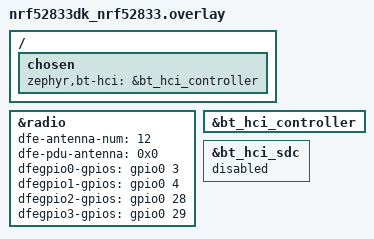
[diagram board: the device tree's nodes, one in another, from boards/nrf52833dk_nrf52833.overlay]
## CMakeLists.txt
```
#
# Copyright (c) 2021 Nordic Semiconductor ASA
#
# SPDX-License-Identifier: LicenseRef-Nordic-5-Clause

cmake_minimum_required(VERSION 3.20.0)

find_package(Zephyr REQUIRED HINTS $ENV{ZEPHYR_BASE})

project(direction_finding_connectionless)

# NORDIC SDK APP START
target_sources(app PRIVATE
  src/main.c
)
# NORDIC SDK APP END
```

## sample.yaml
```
sample:
  name: Direction Finding Connectionless Beacon
  description: Sample application showing connectionless Direction Finding transmission
common:
  tags:
    - bluetooth
    - sysbuild
    - ci_samples_bluetooth
tests:
  sample.bluetooth.direction_finding_connectionless_tx.aoa.sdc:
    sysbuild: true
    platform_allow:
      - nrf5340dk/nrf5340/cpuapp
      - nrf54l15dk/nrf54l05/cpuapp
      - nrf54l15dk/nrf54l10/cpuapp
      - nrf54l15dk/nrf54l15/cpuapp
      - nrf54lm20dk/nrf54lm20a/cpuapp
      - nrf54lm20dk/nrf54lm20b/cpuapp
      - nrf54lv10dk/nrf54lv10a/cpuapp
      - nrf54lv10dk/nrf54lv10a/cpuapp/ns
      - nrf54lc10dk/nrf54lc10a/cpuapp
      - nrf54lc10dk/nrf54lc10a/cpuapp/ns
    integration_platforms:
      - nrf5340dk/nrf5340/cpuapp
      - nrf54l15dk/nrf54l15/cpuapp
    harness: console
    harness_config:
      type: multi_line
      ordered: true
      regex:
        - "Starting Connectionless Beacon Demo"
        - "Bluetooth initialization...success"
        - "Periodic advertising enable...success"
        - "Extended advertising enable...success"
    timeout: 15
  sample.bluetooth.direction_finding_connectionless_tx.aoa.bt_ll_sw_split.nrf53:
    sysbuild: true
    build_only: true
    extra_args:
      - ipc_radio_OVERLAY_CONFIG="../../overlay-bt_ll_sw_split.conf"
      - ipc_radio_SNIPPET="bt-ll-sw-split"
    platform_allow:
      - nrf5340dk/nrf5340/cpuapp
    integration_platforms:
      - nrf5340dk/nrf5340/cpuapp
  sample.bluetooth.direction_finding_connectionless_tx.aod.bt_ll_sw_split.nrf53:
    sysbuild: true
    build_only: true
    extra_args:
      - OVERLAY_CONFIG="overlay-aod.conf"
      - ipc_radio_OVERLAY_CONFIG="../../overlay-bt_ll_sw_split.conf"
      - ipc_radio_SNIPPET="bt-ll-sw-split"
    platform_allow:
      - nrf5340dk/nrf5340/cpuapp
    integration_platforms:
      - nrf5340dk/nrf5340/cpuapp
```

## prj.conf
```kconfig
#
# Copyright (c) 2021 Nordic Semiconductor ASA
#
# SPDX-License-Identifier: LicenseRef-Nordic-5-Clause
#

CONFIG_BT=y
CONFIG_BT_DEVICE_NAME="DF Connectionless Beacon App"

CONFIG_BT_EXT_ADV=y
CONFIG_BT_PER_ADV=y
CONFIG_BT_BROADCASTER=y

# Enable Direction Finding Feature
CONFIG_BT_DF=y
CONFIG_BT_DF_CONNECTIONLESS_CTE_TX=y

# Disable AoD Feature (antenna switching) in Tx mode in Host
CONFIG_BT_DF_CTE_TX_AOD=n

# Enable old clock_control_nrf api implementation for mpsl to use
CONFIG_CLOCK_CONTROL_NRF=y
```

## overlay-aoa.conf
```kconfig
#
# Copyright (c) 2021 Nordic Semiconductor ASA
#
# SPDX-License-Identifier: LicenseRef-Nordic-5-Clause
#

# Disable AoD Feature (antenna switching) in Tx mode in Controller and Host
CONFIG_BT_CTLR_DF_ANT_SWITCH_TX=n
CONFIG_BT_DF_CTE_TX_AOD=n
```

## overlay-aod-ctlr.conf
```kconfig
#
# Copyright (c) 2021 Nordic Semiconductor ASA
#
# SPDX-License-Identifier: LicenseRef-Nordic-5-Clause
#

# Controller part of the AoD configuration. It belongs to the image that holds
# the Bluetooth controller: the application image on single-core boards, and the
# ipc_radio image on boards with a dedicated radio core (nRF53). In an image
# without the controller, HAS_BT_CTLR is not set and this line has no effect.
CONFIG_BT_CTLR_DF_ANT_SWITCH_TX=y
```

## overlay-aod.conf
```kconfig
#
# Copyright (c) 2021 Nordic Semiconductor ASA
#
# SPDX-License-Identifier: LicenseRef-Nordic-5-Clause
#

# Enable AoD Feature (antenna switching) in Tx mode in the Host
# Ineffective here: unsatisfied dependencies BT_CTLR_DF_CTE_TX, BT_CTLR_DF, HAS_BT_CTLR, so
# BT_CTLR_DF_ANT_SWITCH_TX stays n whenever this overlay is applied to an image without the
# controller; moved to overlay-aod-ctlr.conf, which is applied to the image that holds it.
# CONFIG_BT_CTLR_DF_ANT_SWITCH_TX=y
CONFIG_BT_DF_CTE_TX_AOD=y
```

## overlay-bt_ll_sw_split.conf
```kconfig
#
# Copyright (c) 2021 Nordic Semiconductor ASA
#
# SPDX-License-Identifier: LicenseRef-Nordic-5-Clause
#

CONFIG_BT_CTLR_ADV_EXT=y
CONFIG_BT_CTLR_ADV_PERIODIC=y

# Enable Direction Finding TX Feature
CONFIG_BT_CTLR_DF=y

# Disable Direction Finding RX mode
CONFIG_BT_CTLR_DF_ANT_SWITCH_RX=n
CONFIG_BT_CTLR_DF_SCAN_CTE_RX=n

# Enable chaining of multiple CTEs in periodic advertising
CONFIG_BT_CTLR_ADVANCED_FEATURES=y
CONFIG_BT_CTLR_ADV_SYNC_PDU_BACK2BACK=y
CONFIG_BT_CTLR_DF_PER_ADV_CTE_NUM_MAX=16
```

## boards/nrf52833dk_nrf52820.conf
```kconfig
#
# Copyright (c) 2021 Nordic Semiconductor ASA
#
# SPDX-License-Identifier: LicenseRef-Nordic-5-Clause
#

# Enable Direction Finding TX Feature
CONFIG_BT_CTLR_DF=y

# Disable Direction Finding RX mode
CONFIG_BT_CTLR_DF_ANT_SWITCH_RX=n
CONFIG_BT_CTLR_DF_SCAN_CTE_RX=n

# Disable AoD Feature (antenna switching) in Tx mode in Controller
CONFIG_BT_CTLR_DF_ANT_SWITCH_TX=n
```

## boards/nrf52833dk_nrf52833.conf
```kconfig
#
# Copyright (c) 2021 Nordic Semiconductor ASA
#
# SPDX-License-Identifier: LicenseRef-Nordic-5-Clause
#
# Enable Direction Finding Feature
CONFIG_BT_CTLR_DF=y

# Disable Direction Finding RX mode
CONFIG_BT_CTLR_DF_SCAN_CTE_RX=n
CONFIG_BT_CTLR_DF_ANT_SWITCH_RX=n

# Disable AoD Feature (antenna switching) in Tx mode in Controller
CONFIG_BT_CTLR_DF_ANT_SWITCH_TX=n
```

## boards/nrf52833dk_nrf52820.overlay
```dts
/*
 * Copyright (c) 2021 Nordic Semiconductor ASA
 *
 * SPDX-License-Identifier: LicenseRef-Nordic-5-Clause
 */

&radio {
	status = "okay";
	/* This is a number of antennas that are available on antenna matrix
	 * designed by Nordic. For more information see README.rst.
	 */
	dfe-antenna-num = <12>;
	/* This is a setting that enables antenna 12 (in antenna matrix designed
	 * by Nordic) for Tx PDU. For more information see README.rst.
	 */
	dfe-pdu-antenna = <0x0>;

	/* These are GPIO pin numbers that are provided to
	 * Radio peripheral. The pins will be acquired by Radio to
	 * drive antenna switching when AoD is enabled.
	 * Pin numbers are selected to drive switches on antenna matrix
	 * desinged by Nordic. For more information see README.rst.
	 */
	dfegpio0-gpios = <&gpio0 3 0>;
	dfegpio1-gpios = <&gpio0 4 0>;
	dfegpio2-gpios = <&gpio0 28 0>;
	dfegpio3-gpios = <&gpio0 29 0>;
};
```

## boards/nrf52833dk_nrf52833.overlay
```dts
/*
 * Copyright (c) 2021 Nordic Semiconductor ASA
 *
 * SPDX-License-Identifier: LicenseRef-Nordic-5-Clause
 */

&radio {
	status = "okay";
	/* This is a number of antennas that are available on antenna matrix
	 * designed by Nordic. For more information see README.rst.
	 */
	dfe-antenna-num = <12>;
	/* This is a setting that enables antenna 12 (in antenna matrix designed
	 * by Nordic) for Tx PDU. For more information see README.rst.
	 */
	dfe-pdu-antenna = <0x0>;

	/* These are GPIO pin numbers that are provided to
	 * Radio peripheral. The pins will be acquired by Radio to
	 * drive antenna switching when AoD is enabled.
	 * Pin numbers are selected to drive switches on antenna matrix
	 * desinged by Nordic. For more information see README.rst.
	 */
	dfegpio0-gpios = <&gpio0 3 0>;
	dfegpio1-gpios = <&gpio0 4 0>;
	dfegpio2-gpios = <&gpio0 28 0>;
	dfegpio3-gpios = <&gpio0 29 0>;
};

&bt_hci_controller {
	status = "okay";
};

&bt_hci_sdc {
	status = "disabled";
};

/ {
	chosen {
		zephyr,bt-hci = &bt_hci_controller;
	};
};
```

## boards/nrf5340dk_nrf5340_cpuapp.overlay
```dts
/*
 * Copyright (c) 2022 Nordic Semiconductor ASA
 *
 * SPDX-License-Identifier: LicenseRef-Nordic-5-Clause
 */

/* Enable pin forwarding to the network core. The selected pins will be used by
 * the Radio Direction Finding Extension for antenna switching purposes.
 *
 * Note: Pay attention to assigning the same GPIO pins as those provided in
 * the network core DTS overlay.
 */
&gpio_fwd {
	dfe-gpio-if {
		gpios = <&gpio0 4 0>,
			<&gpio0 5 0>,
			<&gpio0 6 0>,
			<&gpio0 7 0>;
		};
};
```

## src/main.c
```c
/*
 * Copyright (c) 2021 Nordic Semiconductor ASA
 *
 * SPDX-License-Identifier: LicenseRef-Nordic-5-Clause
 */

#include <zephyr/types.h>
#include <stddef.h>
#include <errno.h>
#include <zephyr/kernel.h>
#include <zephyr/sys/printk.h>

#include <zephyr/bluetooth/bluetooth.h>
#include <zephyr/bluetooth/direction.h>
#include <zephyr/sys/byteorder.h>
#include <zephyr/sys/util.h>

/* Length of CTE in unit of 8[us] */
#define CTE_LEN (0x14U)
/* Number of CTE send in single periodic advertising train */
#define PER_ADV_EVENT_CTE_COUNT 5

static const struct bt_data ad[] = {
	BT_DATA(BT_DATA_NAME_COMPLETE, CONFIG_BT_DEVICE_NAME, sizeof(CONFIG_BT_DEVICE_NAME) - 1),
};

static void adv_sent_cb(struct bt_le_ext_adv *adv,
			struct bt_le_ext_adv_sent_info *info);

const static struct bt_le_ext_adv_cb adv_callbacks = {
	.sent = adv_sent_cb,
};

static struct bt_le_ext_adv *adv_set;

const static struct bt_le_adv_param param =
		BT_LE_ADV_PARAM_INIT(BT_LE_ADV_OPT_EXT_ADV,
				     BT_GAP_ADV_FAST_INT_MIN_2,
				     BT_GAP_ADV_FAST_INT_MAX_2,
				     NULL);

static struct bt_le_ext_adv_start_param ext_adv_start_param = {
	.timeout = 0,
	.num_events = 0,
};

const static struct bt_le_per_adv_param per_adv_param = {
	.interval_min = BT_GAP_PER_ADV_SLOW_INT_MIN,
	.interval_max = BT_GAP_PER_ADV_SLOW_INT_MAX,
	.options = BT_LE_ADV_OPT_USE_TX_POWER,
};

#if defined(CONFIG_BT_DF_CTE_TX_AOD)
/* Example sequence of antenna switch patterns for antenna matrix designed by
 * Nordic. For more information about antenna switch patterns see README.rst.
 */
static uint8_t ant_patterns[] = {0x2, 0x0, 0x5, 0x6, 0x1, 0x4, 0xC, 0x9, 0xE,
				 0xD, 0x8, 0xA};
#endif /* CONFIG_BT_DF_CTE_TX_AOD */

struct bt_df_adv_cte_tx_param cte_params = { .cte_len = CTE_LEN,
					     .cte_count = PER_ADV_EVENT_CTE_COUNT,
#if defined(CONFIG_BT_DF_CTE_TX_AOD)
					     .cte_type = BT_DF_CTE_TYPE_AOD_2US,
					     .num_ant_ids = ARRAY_SIZE(ant_patterns),
					     .ant_ids = ant_patterns
#else
					     .cte_type = BT_DF_CTE_TYPE_AOA,
					     .num_ant_ids = 0,
					     .ant_ids = NULL
#endif /* CONFIG_BT_DF_CTE_TX_AOD */
};

static void adv_sent_cb(struct bt_le_ext_adv *adv,
			struct bt_le_ext_adv_sent_info *info)
{
	printk("Advertiser[%d] %p sent %d\n", bt_le_ext_adv_get_index(adv),
	       adv, info->num_sent);
}

int main(void)
{
	char addr_s[BT_ADDR_LE_STR_LEN];
	struct bt_le_oob oob_local;
	int err;

	printk("Starting Connectionless Beacon Demo\n");

	/* Initialize the Bluetooth Subsystem */
	printk("Bluetooth initialization...");
	err = bt_enable(NULL);
	if (err) {
		printk("failed (err %d)\n", err);
		return 0;
	}
	printk("success\n");

	printk("Advertising set create...");
	err = bt_le_ext_adv_create(&param, &adv_callbacks, &adv_set);
	if (err) {
		printk("failed (err %d)\n", err);
		return 0;
	}
	printk("success\n");

	printk("Set advertising data...");
	err = bt_le_ext_adv_set_data(adv_set, ad, ARRAY_SIZE(ad), NULL, 0);
	if (err) {
		printk("failed (err %d)\n", err);
		return 0;
	}
	printk("success\n");

	printk("Update CTE params...");
	err = bt_df_set_adv_cte_tx_param(adv_set, &cte_params);
	if (err) {
		printk("failed (err %d)\n", err);
		return 0;
	}
	printk("success\n");

	printk("Periodic advertising params set...");
	err = bt_le_per_adv_set_param(adv_set, &per_adv_param);
	if (err) {
		printk("failed (err %d)\n", err);
		return 0;
	}
	printk("success\n");

	printk("Enable CTE...");
	err = bt_df_adv_cte_tx_enable(adv_set);
	if (err) {
		printk("failed (err %d)\n", err);
		return 0;
	}
	printk("success\n");

	printk("Periodic advertising enable...");
	err = bt_le_per_adv_start(adv_set);
	if (err) {
		printk("failed (err %d)\n", err);
		return 0;
	}
	printk("success\n");

	printk("Extended advertising enable...");
	err = bt_le_ext_adv_start(adv_set, &ext_adv_start_param);
	if (err) {
		printk("failed (err %d)\n", err);
		return 0;
	}
	printk("success\n");

	bt_le_ext_adv_oob_get_local(adv_set, &oob_local);
	bt_addr_le_to_str(&oob_local.addr, addr_s, sizeof(addr_s));

	printk("Started extended advertising as %s\n", addr_s);

	return 0;
}
```
